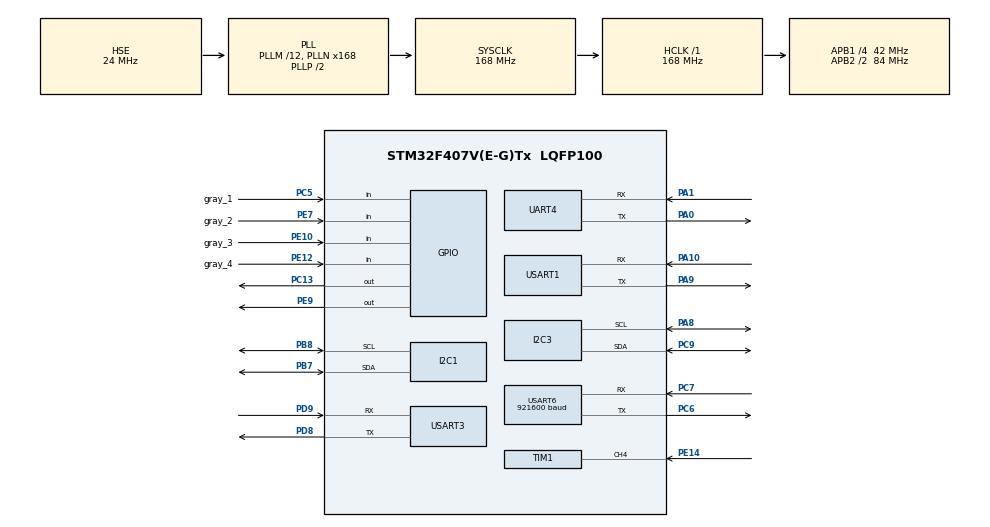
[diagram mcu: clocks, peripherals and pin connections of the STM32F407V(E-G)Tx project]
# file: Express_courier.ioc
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Dma.Request0=USART6_RX
Dma.Request1=USART3_RX
Dma.Request2=UART4_RX
Dma.Request3=USART1_RX
Dma.UART4_RX.2.Direction=DMA_PERIPH_TO_MEMORY
Dma.UART4_RX.2.FIFOMode=DMA_FIFOMODE_DISABLE
Dma.UART4_RX.2.Instance=DMA1_Stream2
Dma.UART4_RX.2.MemDataAlignment=DMA_MDATAALIGN_BYTE
Dma.UART4_RX.2.MemInc=DMA_MINC_ENABLE
Dma.UART4_RX.2.Mode=DMA_NORMAL
Dma.UART4_RX.2.PeriphDataAlignment=DMA_PDATAALIGN_BYTE
Dma.UART4_RX.2.PeriphInc=DMA_PINC_DISABLE
Dma.UART4_RX.2.Priority=DMA_PRIORITY_LOW
Dma.USART1_RX.3.Direction=DMA_PERIPH_TO_MEMORY
Dma.USART1_RX.3.FIFOMode=DMA_FIFOMODE_DISABLE
Dma.USART1_RX.3.Instance=DMA2_Stream2
Dma.USART1_RX.3.MemDataAlignment=DMA_MDATAALIGN_BYTE
Dma.USART1_RX.3.MemInc=DMA_MINC_ENABLE
Dma.USART1_RX.3.Mode=DMA_NORMAL
Dma.USART1_RX.3.PeriphDataAlignment=DMA_PDATAALIGN_BYTE
Dma.USART1_RX.3.PeriphInc=DMA_PINC_DISABLE
Dma.USART1_RX.3.Priority=DMA_PRIORITY_LOW
Dma.USART3_RX.1.Direction=DMA_PERIPH_TO_MEMORY
Dma.USART3_RX.1.FIFOMode=DMA_FIFOMODE_DISABLE
Dma.USART3_RX.1.Instance=DMA1_Stream1
Dma.USART3_RX.1.MemDataAlignment=DMA_MDATAALIGN_BYTE
Dma.USART3_RX.1.MemInc=DMA_MINC_ENABLE
Dma.USART3_RX.1.Mode=DMA_NORMAL
Dma.USART3_RX.1.PeriphDataAlignment=DMA_PDATAALIGN_BYTE
Dma.USART3_RX.1.PeriphInc=DMA_PINC_DISABLE
Dma.USART3_RX.1.Priority=DMA_PRIORITY_LOW
Dma.USART6_RX.0.Direction=DMA_PERIPH_TO_MEMORY
Dma.USART6_RX.0.FIFOMode=DMA_FIFOMODE_DISABLE
Dma.USART6_RX.0.Instance=DMA2_Stream1
Dma.USART6_RX.0.MemDataAlignment=DMA_MDATAALIGN_BYTE
Dma.USART6_RX.0.MemInc=DMA_MINC_ENABLE
Dma.USART6_RX.0.Mode=DMA_NORMAL
Dma.USART6_RX.0.PeriphDataAlignment=DMA_PDATAALIGN_BYTE
Dma.USART6_RX.0.PeriphInc=DMA_PINC_DISABLE
Dma.USART6_RX.0.Priority=DMA_PRIORITY_LOW
FREERTOS.Tasks01=defaultTask,0,128,StartDefaultTask,Default,NULL,Dynamic,NULL,NULL
FREERTOS.configENABLE_FPU=1
Mcu.Family=STM32F4
Mcu.Name=STM32F407V(E-G)Tx
Mcu.Package=LQFP100
NVIC.DMA1_Stream1_IRQn=true\:5\:0\:false\:false\:true\:true\:false\:true\:true
NVIC.DMA1_Stream2_IRQn=true\:5\:0\:false\:false\:true\:true\:false\:true\:true
NVIC.DMA2_Stream1_IRQn=true\:5\:0\:false\:false\:true\:true\:false\:true\:true
NVIC.DMA2_Stream2_IRQn=true\:5\:0\:false\:false\:true\:true\:false\:true\:true
NVIC.PriorityGroup=NVIC_PRIORITYGROUP_4
NVIC.TIM1_BRK_TIM9_IRQn=true\:5\:0\:false\:false\:true\:true\:true\:true\:true
NVIC.TIM1_CC_IRQn=true\:5\:0\:false\:false\:true\:true\:true\:true\:true
NVIC.TIM1_TRG_COM_TIM11_IRQn=true\:5\:0\:false\:false\:true\:true\:true\:true\:true
NVIC.TIM1_UP_TIM10_IRQn=true\:5\:0\:false\:false\:true\:true\:true\:true\:true
NVIC.UART4_IRQn=true\:5\:0\:false\:false\:true\:true\:true\:true\:true
NVIC.USART1_IRQn=true\:5\:0\:false\:false\:true\:true\:true\:true\:true
NVIC.USART3_IRQn=true\:5\:0\:false\:false\:true\:true\:true\:true\:true
NVIC.USART6_IRQn=true\:5\:0\:false\:false\:true\:true\:true\:true\:true
PA0-WKUP.Mode=Asynchronous
PA0-WKUP.Signal=UART4_TX
PA1.Mode=Asynchronous
PA1.Signal=UART4_RX
PA10.Mode=Asynchronous
PA10.Signal=USART1_RX
PA13.Mode=Serial_Wire
PA13.Signal=SYS_JTMS-SWDIO
PA14.Mode=Serial_Wire
PA14.Signal=SYS_JTCK-SWCLK
PA8.Mode=I2C
PA8.Signal=I2C3_SCL
PA9.Mode=Asynchronous
PA9.Signal=USART1_TX
PB7.Mode=I2C
PB7.Signal=I2C1_SDA
PB8.Mode=I2C
PB8.Signal=I2C1_SCL
PC13-ANTI_TAMP.Signal=GPIO_Output
PC5.GPIO_Label=gray_1
PC5.Signal=GPIO_Input
PC6.Mode=Asynchronous
PC6.Signal=USART6_TX
PC7.Mode=Asynchronous
PC7.Signal=USART6_RX
PC9.Mode=I2C
PC9.Signal=I2C3_SDA
PD8.Mode=Asynchronous
PD8.Signal=USART3_TX
PD9.Mode=Asynchronous
PD9.Signal=USART3_RX
PE10.GPIO_Label=gray_3
PE10.Signal=GPIO_Input
PE12.GPIO_Label=gray_4
PE12.Signal=GPIO_Input
PE14.Signal=S_TIM1_CH4
PE7.GPIO_Label=gray_2
PE7.Signal=GPIO_Input
PE9.Signal=GPIO_Output
PH0-OSC_IN.Mode=HSE-External-Oscillator
PH0-OSC_IN.Signal=RCC_OSC_IN
PH1-OSC_OUT.Mode=HSE-External-Oscillator
PH1-OSC_OUT.Signal=RCC_OSC_OUT
ProjectManager.HeapSize=0x2000
ProjectManager.StackSize=0x800
ProjectManager.TargetToolchain=MDK-ARM V5.32
RCC.48MHZClocksFreq_Value=84000000
RCC.AHBFreq_Value=168000000
RCC.APB1CLKDivider=RCC_HCLK_DIV4
RCC.APB1Freq_Value=42000000
RCC.APB1TimFreq_Value=84000000
RCC.APB2CLKDivider=RCC_HCLK_DIV2
RCC.APB2Freq_Value=84000000
RCC.APB2TimFreq_Value=168000000
RCC.CortexFreq_Value=168000000
RCC.HCLKFreq_Value=168000000
RCC.HSE_VALUE=24000000
RCC.HSI_VALUE=16000000
RCC.LSE_VALUE=32768
RCC.PLLM=12
RCC.PLLN=168
RCC.PLLSourceVirtual=RCC_PLLSOURCE_HSE
RCC.SYSCLKFreq_VALUE=168000000
RCC.SYSCLKSource=RCC_SYSCLKSOURCE_PLLCLK
RCC.VCOOutputFreq_Value=336000000
SH.S_TIM1_CH4.0=TIM1_CH4,Input_Capture4_from_TI4
TIM1.AutoReloadPreload=TIM_AUTORELOAD_PRELOAD_ENABLE
TIM1.Channel-Input_Capture4_from_TI4=TIM_CHANNEL_4
TIM1.Prescaler=168-1
TIM10.AutoReloadPreload=TIM_AUTORELOAD_PRELOAD_ENABLE
TIM10.Period=10-1
TIM10.Prescaler=168-1
UART4.VirtualMode=Asynchronous
USART1.VirtualMode=VM_ASYNC
USART3.VirtualMode=VM_ASYNC
USART6.BaudRate=921600
USART6.VirtualMode=VM_ASYNC
VP_FREERTOS_VS_CMSIS_V1.Mode=CMSIS_V1
VP_TIM10_VS_ClockSourceINT.Mode=Enable_Timer
VP_TIM1_VS_ClockSourceINT.Mode=Internal
board=custom

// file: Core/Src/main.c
/* USER CODE BEGIN Header */
/**
  ******************************************************************************
  * @file           : main.c
  * @brief          : Main program body
  ******************************************************************************
  * @attention
  *
  * Copyright (c) 2025 STMicroelectronics.
  * All rights reserved.
  *
  * This software is licensed under terms that can be found in the LICENSE file
  * in the root directory of this software component.
  * If no LICENSE file comes with this software, it is provided AS-IS.
  *
  ******************************************************************************
  */
/* USER CODE END Header */
#include "main.h"
#include "cmsis_os.h"
#include "dma.h"
#include "i2c.h"
#include "tim.h"
#include "usart.h"
#include "gpio.h"

/* USER CODE BEGIN Includes */
#include "maincpp.h"

/* USER CODE END Includes */

void SystemClock_Config(void);
void MX_FREERTOS_Init(void);

int main(void)
{

  /* MCU Configuration--------------------------------------------------------*/

  /* Reset of all peripherals, Initializes the Flash interface and the Systick. */
  HAL_Init();

  /* Configure the system clock */
  SystemClock_Config();

  /* Initialize all configured peripherals */
  MX_GPIO_Init();
  MX_DMA_Init();
  MX_USART3_UART_Init();
  MX_USART6_UART_Init();
  MX_UART4_Init();
  MX_I2C1_Init();
  MX_I2C3_Init();
  MX_TIM1_Init();
  MX_TIM10_Init();
  MX_USART1_UART_Init();
  /* USER CODE BEGIN 2 */
  main_cpp();
  /* USER CODE END 2 */

  /* Call init function for freertos objects (in cmsis_os2.c) */
  MX_FREERTOS_Init();

  /* Start scheduler */
  osKernelStart();

  /* We should never get here as control is now taken by the scheduler */

  /* Infinite loop */
  while (1)
  {

    /* USER CODE BEGIN 3 */
//		SR04_GetData(  );
//      HAL_Delay(1500);

  }
  /* USER CODE END 3 */
}

void SystemClock_Config(void)
{
  RCC_OscInitTypeDef RCC_OscInitStruct = {0};
  RCC_ClkInitTypeDef RCC_ClkInitStruct = {0};

  /** Configure the main internal regulator output voltage
  */
  __HAL_RCC_PWR_CLK_ENABLE();
  __HAL_PWR_VOLTAGESCALING_CONFIG(PWR_REGULATOR_VOLTAGE_SCALE1);

  /** Initializes the RCC Oscillators according to the specified parameters
  * in the RCC_OscInitTypeDef structure.
  */
  RCC_OscInitStruct.OscillatorType = RCC_OSCILLATORTYPE_HSE;
  RCC_OscInitStruct.HSEState = RCC_HSE_ON;
  RCC_OscInitStruct.PLL.PLLState = RCC_PLL_ON;
  RCC_OscInitStruct.PLL.PLLSource = RCC_PLLSOURCE_HSE;
  RCC_OscInitStruct.PLL.PLLM = 12;
  RCC_OscInitStruct.PLL.PLLN = 168;
  RCC_OscInitStruct.PLL.PLLP = RCC_PLLP_DIV2;
  RCC_OscInitStruct.PLL.PLLQ = 4;
  if (HAL_RCC_OscConfig(&RCC_OscInitStruct) != HAL_OK)
  {
    Error_Handler();
  }

  /** Initializes the CPU, AHB and APB buses clocks
  */
  RCC_ClkInitStruct.ClockType = RCC_CLOCKTYPE_HCLK|RCC_CLOCKTYPE_SYSCLK
                              |RCC_CLOCKTYPE_PCLK1|RCC_CLOCKTYPE_PCLK2;
  RCC_ClkInitStruct.SYSCLKSource = RCC_SYSCLKSOURCE_PLLCLK;
  RCC_ClkInitStruct.AHBCLKDivider = RCC_SYSCLK_DIV1;
  RCC_ClkInitStruct.APB1CLKDivider = RCC_HCLK_DIV4;
  RCC_ClkInitStruct.APB2CLKDivider = RCC_HCLK_DIV2;

  if (HAL_RCC_ClockConfig(&RCC_ClkInitStruct, FLASH_LATENCY_5) != HAL_OK)
  {
    Error_Handler();
  }
}

void Error_Handler(void)
{
  __disable_irq();
  while (1)
  {
  }
}
